AUTOSAR XML (schema 4-0-3)
package /ComponentTypes
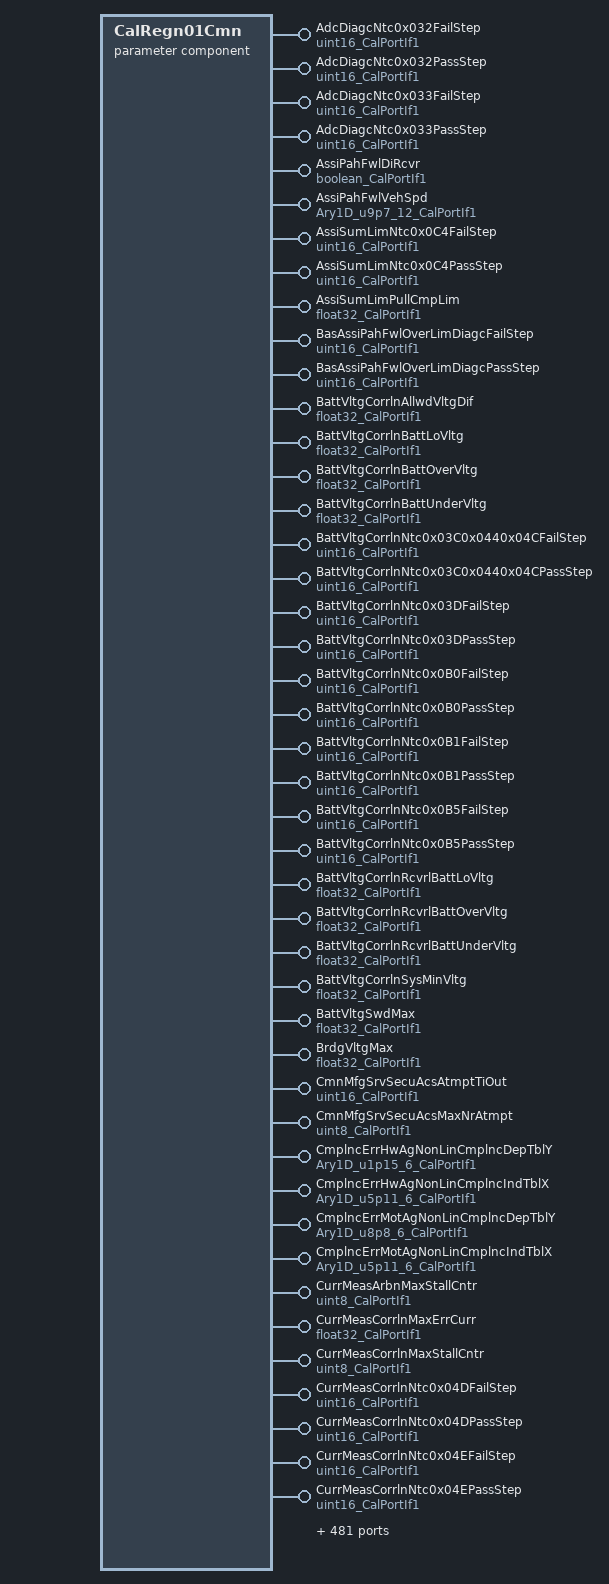
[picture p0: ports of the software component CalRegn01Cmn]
  parameter sw component type CalRegn01Cmn
    525 x provide port:
      AdcDiagcNtc0x032FailStep: parameter-provide-com-spec{init-value=6554, parameter=Val}, provided-interface=uint16_CalPortIf1
      AdcDiagcNtc0x032PassStep: parameter-provide-com-spec{init-value=65, parameter=Val}, provided-interface=uint16_CalPortIf1
      AdcDiagcNtc0x033FailStep: parameter-provide-com-spec{init-value=6554, parameter=Val}, provided-interface=uint16_CalPortIf1
      AdcDiagcNtc0x033PassStep: parameter-provide-com-spec{init-value=65, parameter=Val}, provided-interface=uint16_CalPortIf1
      AssiPahFwlDiRcvr: parameter-provide-com-spec{init-value=0, parameter=Logl}, provided-interface=boolean_CalPortIf1
      AssiPahFwlVehSpd: parameter-provide-com-spec{init-value=[0, 256, 1280, 3200, 6400, 9600, 12800, 19200, 25600, 31872, 32000, 32128], parameter=Ary1D}, provided-interface=Ary1D_u9p7_12_CalPortIf1
      AssiSumLimNtc0x0C4FailStep: parameter-provide-com-spec{init-value=65535, parameter=Val}, provided-interface=uint16_CalPortIf1
      AssiSumLimNtc0x0C4PassStep: parameter-provide-com-spec{init-value=65535, parameter=Val}, provided-interface=uint16_CalPortIf1
      AssiSumLimPullCmpLim: parameter-provide-com-spec{init-value=8.8, parameter=Val}, provided-interface=float32_CalPortIf1
      BasAssiPahFwlOverLimDiagcFailStep: parameter-provide-com-spec{init-value=1311, parameter=Val}, provided-interface=uint16_CalPortIf1
      BasAssiPahFwlOverLimDiagcPassStep: parameter-provide-com-spec{init-value=1311, parameter=Val}, provided-interface=uint16_CalPortIf1
      BattVltgCorrlnAllwdVltgDif: parameter-provide-com-spec{init-value=0.73, parameter=Val}, provided-interface=float32_CalPortIf1
      BattVltgCorrlnBattLoVltg: parameter-provide-com-spec{init-value=10, parameter=Val}, provided-interface=float32_CalPortIf1
      BattVltgCorrlnBattOverVltg: parameter-provide-com-spec{init-value=16, parameter=Val}, provided-interface=float32_CalPortIf1
      BattVltgCorrlnBattUnderVltg: parameter-provide-com-spec{init-value=9, parameter=Val}, provided-interface=float32_CalPortIf1
      BattVltgCorrlnNtc0x03C0x0440x04CFailStep: parameter-provide-com-spec{init-value=410, parameter=Val}, provided-interface=uint16_CalPortIf1
      BattVltgCorrlnNtc0x03C0x0440x04CPassStep: parameter-provide-com-spec{init-value=272, parameter=Val}, provided-interface=uint16_CalPortIf1
      BattVltgCorrlnNtc0x03DFailStep: parameter-provide-com-spec{init-value=410, parameter=Val}, provided-interface=uint16_CalPortIf1
      BattVltgCorrlnNtc0x03DPassStep: parameter-provide-com-spec{init-value=272, parameter=Val}, provided-interface=uint16_CalPortIf1
      BattVltgCorrlnNtc0x0B0FailStep: parameter-provide-com-spec{init-value=327, parameter=Val}, provided-interface=uint16_CalPortIf1
      BattVltgCorrlnNtc0x0B0PassStep: parameter-provide-com-spec{init-value=327, parameter=Val}, provided-interface=uint16_CalPortIf1
      BattVltgCorrlnNtc0x0B1FailStep: parameter-provide-com-spec{init-value=327, parameter=Val}, provided-interface=uint16_CalPortIf1
      BattVltgCorrlnNtc0x0B1PassStep: parameter-provide-com-spec{init-value=327, parameter=Val}, provided-interface=uint16_CalPortIf1
      BattVltgCorrlnNtc0x0B5FailStep: parameter-provide-com-spec{init-value=327, parameter=Val}, provided-interface=uint16_CalPortIf1
      BattVltgCorrlnNtc0x0B5PassStep: parameter-provide-com-spec{init-value=327, parameter=Val}, provided-interface=uint16_CalPortIf1
      BattVltgCorrlnRcvrlBattLoVltg: parameter-provide-com-spec{init-value=10.5, parameter=Val}, provided-interface=float32_CalPortIf1
      BattVltgCorrlnRcvrlBattOverVltg: parameter-provide-com-spec{init-value=15.5, parameter=Val}, provided-interface=float32_CalPortIf1
      BattVltgCorrlnRcvrlBattUnderVltg: parameter-provide-com-spec{init-value=9.5, parameter=Val}, provided-interface=float32_CalPortIf1
      BattVltgCorrlnSysMinVltg: parameter-provide-com-spec{init-value=6, parameter=Val}, provided-interface=float32_CalPortIf1
      BattVltgSwdMax: parameter-provide-com-spec{init-value=16, parameter=Val}, provided-interface=float32_CalPortIf1
      BrdgVltgMax: parameter-provide-com-spec{init-value=26.5, parameter=Val}, provided-interface=float32_CalPortIf1
      CmnMfgSrvSecuAcsAtmptTiOut: parameter-provide-com-spec{init-value=2500, parameter=Val}, provided-interface=uint16_CalPortIf1
      CmnMfgSrvSecuAcsMaxNrAtmpt: parameter-provide-com-spec{init-value=3, parameter=Val}, provided-interface=uint8_CalPortIf1
      CmplncErrHwAgNonLinCmplncDepTblY: parameter-provide-com-spec{init-value=6 x 0, parameter=Ary1D}, provided-interface=Ary1D_u1p15_6_CalPortIf1
      CmplncErrHwAgNonLinCmplncIndTblX: parameter-provide-com-spec{init-value=[0, 1024, 3072, 6144, 10240, 16384], parameter=Ary1D}, provided-interface=Ary1D_u5p11_6_CalPortIf1
      CmplncErrMotAgNonLinCmplncDepTblY: parameter-provide-com-spec{init-value=6 x 0, parameter=Ary1D}, provided-interface=Ary1D_u8p8_6_CalPortIf1
      CmplncErrMotAgNonLinCmplncIndTblX: parameter-provide-com-spec{init-value=[0, 1024, 3072, 6144, 10240, 16384], parameter=Ary1D}, provided-interface=Ary1D_u5p11_6_CalPortIf1
      CurrMeasArbnMaxStallCntr: parameter-provide-com-spec{init-value=20, parameter=Val}, provided-interface=uint8_CalPortIf1
      CurrMeasCorrlnMaxErrCurr: parameter-provide-com-spec{init-value=12, parameter=Val}, provided-interface=float32_CalPortIf1
      CurrMeasCorrlnMaxStallCntr: parameter-provide-com-spec{init-value=200, parameter=Val}, provided-interface=uint8_CalPortIf1
      CurrMeasCorrlnNtc0x04DFailStep: parameter-provide-com-spec{init-value=512, parameter=Val}, provided-interface=uint16_CalPortIf1
      CurrMeasCorrlnNtc0x04DPassStep: parameter-provide-com-spec{init-value=512, parameter=Val}, provided-interface=uint16_CalPortIf1
      CurrMeasCorrlnNtc0x04EFailStep: parameter-provide-com-spec{init-value=512, parameter=Val}, provided-interface=uint16_CalPortIf1
      CurrMeasCorrlnNtc0x04EPassStep: parameter-provide-com-spec{init-value=512, parameter=Val}, provided-interface=uint16_CalPortIf1
      CurrMeasEolFixdPwmPerd: parameter-provide-com-spec{init-value=62500, parameter=Val}, provided-interface=uint32_CalPortIf1
      CurrMeasEolGainMax: parameter-provide-com-spec{init-value=76, parameter=Val}, provided-interface=float32_CalPortIf1
      CurrMeasEolGainMin: parameter-provide-com-spec{init-value=56, parameter=Val}, provided-interface=float32_CalPortIf1
      CurrMeasEolGainNrOfSample: parameter-provide-com-spec{init-value=5, parameter=Val}, provided-interface=uint16_CalPortIf1
      CurrMeasEolGainNumer: parameter-provide-com-spec{init-value=45, parameter=Val}, provided-interface=float32_CalPortIf1
      CurrMeasEolMaxMotVel: parameter-provide-com-spec{init-value=16, parameter=Val}, provided-interface=float32_CalPortIf1
      CurrMeasEolOffsHiBrdgVltgMin: parameter-provide-com-spec{init-value=262500, parameter=Val}, provided-interface=float32_CalPortIf1
      CurrMeasEolOffsHiCmuOffs: parameter-provide-com-spec{init-value=50000, parameter=Val}, provided-interface=uint32_CalPortIf1
      CurrMeasEolOffsLoCmuOffs: parameter-provide-com-spec{init-value=6250, parameter=Val}, provided-interface=uint32_CalPortIf1
      CurrMeasEolOffsMax: parameter-provide-com-spec{init-value=2.8, parameter=Val}, provided-interface=float32_CalPortIf1
      CurrMeasEolOffsMin: parameter-provide-com-spec{init-value=2.3, parameter=Val}, provided-interface=float32_CalPortIf1
      CurrMeasEolOffsNrOfSample: parameter-provide-com-spec{init-value=20, parameter=Val}, provided-interface=uint16_CalPortIf1
      CurrMeasEolTranCntrThd: parameter-provide-com-spec{init-value=5, parameter=Val}, provided-interface=uint8_CalPortIf1
      CurrMeasMinRqrdPhaOnTi: parameter-provide-com-spec{init-value=11000, parameter=Val}, provided-interface=uint32_CalPortIf1
      CurrMeasMotAgCompuDly: parameter-provide-com-spec{init-value=30000, parameter=Val}, provided-interface=uint32_CalPortIf1
      CurrMeasMotCurrAdcVlyWrmIninMax: parameter-provide-com-spec{init-value=3, parameter=Val}, provided-interface=float32_CalPortIf1
      CurrMeasMotCurrAdcVlyWrmIninMin: parameter-provide-com-spec{init-value=2, parameter=Val}, provided-interface=float32_CalPortIf1
      CurrMeasNtc0x05DFailStep: parameter-provide-com-spec{init-value=16384, parameter=Val}, provided-interface=uint16_CalPortIf1
      CurrMeasNtc0x05DPassStep: parameter-provide-com-spec{init-value=16384, parameter=Val}, provided-interface=uint16_CalPortIf1
      CurrMeasNtc0x06DFailStep: parameter-provide-com-spec{init-value=16384, parameter=Val}, provided-interface=uint16_CalPortIf1
      CurrMeasNtc0x06DPassStep: parameter-provide-com-spec{init-value=16384, parameter=Val}, provided-interface=uint16_CalPortIf1
      CurrReasbnDiagcCurrDiagcMotEnvlpTblMax: parameter-provide-com-spec{init-value=4.6, parameter=Val}, provided-interface=float32_CalPortIf1
      CurrReasbnDiagcCurrDiagcPrimErrThd: parameter-provide-com-spec{init-value=20, parameter=Val}, provided-interface=float32_CalPortIf1
      CurrReasbnDiagcCurrDiagcSecdryErrThd: parameter-provide-com-spec{init-value=20, parameter=Val}, provided-interface=float32_CalPortIf1
      CurrReasbnDiagcCurrDiagcSecdryTqLimThd: parameter-provide-com-spec{init-value=0, parameter=Val}, provided-interface=float32_CalPortIf1
      CurrReasbnDiagcDiagFildLim: parameter-provide-com-spec{init-value=10, parameter=Val}, provided-interface=float32_CalPortIf1
      CurrReasbnDiagcDiagVltgLpFilEna: parameter-provide-com-spec{init-value=1, parameter=Logl}, provided-interface=boolean_CalPortIf1
      CurrReasbnDiagcDiagVltgLpFilFrq: parameter-provide-com-spec{init-value=5, parameter=Val}, provided-interface=float32_CalPortIf1
      CurrReasbnDiagcLpFilSca: parameter-provide-com-spec{init-value=0.5, parameter=Val}, provided-interface=float32_CalPortIf1
      CurrReasbnDiagcMotVelHiLim: parameter-provide-com-spec{init-value=1350, parameter=Val}, provided-interface=float32_CalPortIf1
      CurrReasbnDiagcMotVelLoLim: parameter-provide-com-spec{init-value=1, parameter=Val}, provided-interface=float32_CalPortIf1
      CurrReasbnDiagcMotVltgDaxLpFilFrq: parameter-provide-com-spec{init-value=250, parameter=Val}, provided-interface=float32_CalPortIf1
      CurrReasbnDiagcMotVltgQaxDaxFilEna: parameter-provide-com-spec{init-value=1, parameter=Logl}, provided-interface=boolean_CalPortIf1
      CurrReasbnDiagcMotVltgQaxLpFilFrq: parameter-provide-com-spec{init-value=250, parameter=Val}, provided-interface=float32_CalPortIf1
      CurrReasbnDiagcVelLpFilEna: parameter-provide-com-spec{init-value=1, parameter=Logl}, provided-interface=boolean_CalPortIf1
      CurrReasbnDiagcVelLpFilFrq: parameter-provide-com-spec{init-value=125, parameter=Val}, provided-interface=float32_CalPortIf1
      DampgPahFwlAssiAddlDampgX: parameter-provide-com-spec{init-value=[0, 3200, 6400, 9600, 12800, 25600, 32736, 35776], parameter=Ary1D}, provided-interface=Ary1D_u11p5_8_CalPortIf1
      DampgPahFwlAssiAddlDampgY: parameter-provide-com-spec{init-value=[0, 6144, 14336, 14336, 14336, 14336, 14336, 14336], parameter=Ary1D}, provided-interface=Ary1D_u5p11_8_CalPortIf1
      DampgPahFwlDampgCmdAddlDampgX: parameter-provide-com-spec{init-value=[0, 3200, 6400, 9600, 12800, 25600, 32736, 35776], parameter=Ary1D}, provided-interface=Ary1D_u11p5_8_CalPortIf1
      DampgPahFwlDampgCmdAddlDampgY: parameter-provide-com-spec{init-value=[0, 6144, 14336, 14336, 14336, 14336, 14336, 14336], parameter=Ary1D}, provided-interface=Ary1D_u5p11_8_CalPortIf1
      DampgPahFwlDampgCmdFwlOverLimDiagcFailStep: parameter-provide-com-spec{init-value=1311, parameter=Val}, provided-interface=uint16_CalPortIf1
      DampgPahFwlDampgCmdFwlOverLimDiagcPassStep: parameter-provide-com-spec{init-value=1311, parameter=Val}, provided-interface=uint16_CalPortIf1
      DampgPahFwlDftDampgX: parameter-provide-com-spec{init-value=[0, 1184, 2368, 3552, 4736, 5920, 7104, 8288, 9472, 10656, 11840], parameter=Ary1D}, provided-interface=Ary1D_u11p5_11_CalPortIf1
      DampgPahFwlInertiaCmpCmdFwlOverLimDiagcFailStep: parameter-provide-com-spec{init-value=1311, parameter=Val}, provided-interface=uint16_CalPortIf1
      DampgPahFwlInertiaCmpCmdFwlOverLimDiagcPassStep: parameter-provide-com-spec{init-value=1311, parameter=Val}, provided-interface=uint16_CalPortIf1
      DampgPahFwlVehSpd: parameter-provide-com-spec{init-value=[0, 256, 1280, 3200, 6400, 9600, 12800, 19200, 25600, 31872, 32000, 32128], parameter=Ary1D}, provided-interface=Ary1D_u9p7_12_CalPortIf1
      DutyCycThermProtnAbsltCtrlTTblX: parameter-provide-com-spec{init-value=[122, 123, 125, 127], parameter=Ary1D}, provided-interface=Ary1D_s15p0_4_CalPortIf1
      DutyCycThermProtnAbsltCtrlTTqTblY: parameter-provide-com-spec{init-value=[346, 287, 234, 0], parameter=Ary1D}, provided-interface=Ary1D_u9p7_4_CalPortIf1
      DutyCycThermProtnAbsltCuTTblX: parameter-provide-com-spec{init-value=[122, 123, 125, 127], parameter=Ary1D}, provided-interface=Ary1D_s15p0_4_CalPortIf1
      DutyCycThermProtnAbsltCuTTqTblY: parameter-provide-com-spec{init-value=[346, 287, 234, 0], parameter=Ary1D}, provided-interface=Ary1D_u9p7_4_CalPortIf1
      DutyCycThermProtnAbsltMotVelBreakPt: parameter-provide-com-spec{init-value=1.375, parameter=Val}, provided-interface=float32_CalPortIf1
      DutyCycThermProtnAbsltTTqSlewHiLim: parameter-provide-com-spec{init-value=0.3, parameter=Val}, provided-interface=float32_CalPortIf1
      DutyCycThermProtnAbsltTTqSlewLoLim: parameter-provide-com-spec{init-value=0.3, parameter=Val}, provided-interface=float32_CalPortIf1
      DutyCycThermProtnCtrlT: parameter-provide-com-spec{init-value=70, parameter=Val}, provided-interface=float32_CalPortIf1
      DutyCycThermProtnCtrlTSeln: parameter-provide-com-spec{init-value=1, parameter=Logl}, provided-interface=boolean_CalPortIf1
      DutyCycThermProtnDutyCycFildThd: parameter-provide-com-spec{init-value=92, parameter=Val}, provided-interface=u16p0_CalPortIf1
      DutyCycThermProtnIgnOffCtrlEna: parameter-provide-com-spec{init-value=0, parameter=Logl}, provided-interface=boolean_CalPortIf1
      DutyCycThermProtnIgnOffMsgWaitTi: parameter-provide-com-spec{init-value=0.5, parameter=Val}, provided-interface=float32_CalPortIf1
      DutyCycThermProtnLstTblValNonStall: parameter-provide-com-spec{init-value=[128, 128, 128, 44, 44], parameter=Ary1D}, provided-interface=Ary1D_u9p7_5_CalPortIf1
      DutyCycThermProtnLstTblValStall: parameter-provide-com-spec{init-value=[124, 124, 124, 40, 40], parameter=Ary1D}, provided-interface=Ary1D_u9p7_5_CalPortIf1
      DutyCycThermProtnMotPrTSeln: parameter-provide-com-spec{init-value=1, parameter=Logl}, provided-interface=boolean_CalPortIf1
      DutyCycThermProtnMplr1NonStallTblY: parameter-provide-com-spec{init-value=[127, 127, 127, 1630, 1630], parameter=Ary1D}, provided-interface=Ary1D_u3p13_5_CalPortIf1
      DutyCycThermProtnMplr1StallTblY: parameter-provide-com-spec{init-value=[133, 133, 133, 180, 180], parameter=Ary1D}, provided-interface=Ary1D_u3p13_5_CalPortIf1
      DutyCycThermProtnMplr2NonStallTblY: parameter-provide-com-spec{init-value=[159, 159, 159, 281, 281], parameter=Ary1D}, provided-interface=Ary1D_u3p13_5_CalPortIf1
      DutyCycThermProtnMplr2StallTblY: parameter-provide-com-spec{init-value=[167, 167, 167, 310, 310], parameter=Ary1D}, provided-interface=Ary1D_u3p13_5_CalPortIf1
      DutyCycThermProtnMplr3NonStallTblY: parameter-provide-com-spec{init-value=[199, 199, 199, 1282, 1282], parameter=Ary1D}, provided-interface=Ary1D_u3p13_5_CalPortIf1
      DutyCycThermProtnMplr3StallTblY: parameter-provide-com-spec{init-value=[210, 210, 210, 1707, 1707], parameter=Ary1D}, provided-interface=Ary1D_u3p13_5_CalPortIf1
      DutyCycThermProtnMplr4NonStallTblY: parameter-provide-com-spec{init-value=5 x 1, parameter=Ary1D}, provided-interface=Ary1D_u3p13_5_CalPortIf1
      DutyCycThermProtnMplr4StallTblY: parameter-provide-com-spec{init-value=5 x 1, parameter=Ary1D}, provided-interface=Ary1D_u3p13_5_CalPortIf1
      DutyCycThermProtnMplr5NonStallTblY: parameter-provide-com-spec{init-value=[998, 998, 998, 9535, 9535], parameter=Ary1D}, provided-interface=Ary1D_u3p13_5_CalPortIf1
      DutyCycThermProtnMplr5StallTblY: parameter-provide-com-spec{init-value=[998, 998, 998, 9535, 9535], parameter=Ary1D}, provided-interface=Ary1D_u3p13_5_CalPortIf1
      DutyCycThermProtnMplr6NonStallTblY: parameter-provide-com-spec{init-value=5 x 1, parameter=Ary1D}, provided-interface=Ary1D_u3p13_5_CalPortIf1
      DutyCycThermProtnMplr6StallTblY: parameter-provide-com-spec{init-value=5 x 1, parameter=Ary1D}, provided-interface=Ary1D_u3p13_5_CalPortIf1
      DutyCycThermProtnMplrTblX: parameter-provide-com-spec{init-value=[-40, 0, 83, 84, 85], parameter=Ary1D}, provided-interface=Ary1D_s15p0_5_CalPortIf1
      DutyCycThermProtnMplrTSeln: parameter-provide-com-spec{init-value=1, parameter=Logl}, provided-interface=boolean_CalPortIf1
      DutyCycThermProtnSlowFilTSeln: parameter-provide-com-spec{init-value=0, parameter=Logl}, provided-interface=boolean_CalPortIf1
      DutyCycThermProtnThermLimScaFac: parameter-provide-com-spec{init-value=0.5, parameter=Val}, provided-interface=float32_CalPortIf1
      DutyCycThermProtnThermLoadLimTblX: parameter-provide-com-spec{init-value=[0, 76, 80, 84, 88, 92, 96, 100], parameter=Ary1D}, provided-interface=Ary1D_u16p0_8_CalPortIf1
      DutyCycThermProtnThermLoadLimTblY: parameter-provide-com-spec{init-value=[346, 346, 346, 346, 287, 234, 181, 128], parameter=Ary1D}, provided-interface=Ary1D_u9p7_8_CalPortIf1
      DutyCycThermProtnTqCmdSlewDwn: parameter-provide-com-spec{init-value=0.3, parameter=Val}, provided-interface=float32_CalPortIf1
      DutyCycThermProtnTqCmdSlewUp: parameter-provide-com-spec{init-value=0.3, parameter=Val}, provided-interface=float32_CalPortIf1
      EcuTMeasDftT: parameter-provide-com-spec{init-value=60, parameter=Val}, provided-interface=float32_CalPortIf1
      EcuTMeasFilTau: parameter-provide-com-spec{init-value=0.5, parameter=Val}, provided-interface=float32_CalPortIf1
      EcuTMeasNtc0x045FailStep: parameter-provide-com-spec{init-value=3000, parameter=Val}, provided-interface=uint16_CalPortIf1
      EcuTMeasNtc0x045PassStep: parameter-provide-com-spec{init-value=3000, parameter=Val}, provided-interface=uint16_CalPortIf1
      EcuTMeasRngDiagcMax: parameter-provide-com-spec{init-value=145, parameter=Val}, provided-interface=float32_CalPortIf1
      EcuTMeasRngDiagcMin: parameter-provide-com-spec{init-value=-45, parameter=Val}, provided-interface=float32_CalPortIf1
      EcuTMeasScag: parameter-provide-com-spec{init-value=100, parameter=Val}, provided-interface=float32_CalPortIf1
      EcuTMeasScagOffs: parameter-provide-com-spec{init-value=-50, parameter=Val}, provided-interface=float32_CalPortIf1
      ElecPwrCnsCtrlrInpR: parameter-provide-com-spec{init-value=0.0005, parameter=Val}, provided-interface=float32_CalPortIf1
      EotLrngHwAgOverTrvlCnt: parameter-provide-com-spec{init-value=5, parameter=Val}, provided-interface=uint8_CalPortIf1
      EotProtnFwlEotDampgActvBndX: parameter-provide-com-spec{init-value=[-11200, -80, 160, 800, 11200], parameter=Ary1D}, provided-interface=Ary1D_s11p4_5_CalPortIf1
      EotProtnFwlInactvLim: parameter-provide-com-spec{init-value=0.1, parameter=Val}, provided-interface=float32_CalPortIf1
      EotProtnFwlVehSpd: parameter-provide-com-spec{init-value=[0, 2560, 5120, 7680], parameter=Ary1D}, provided-interface=Ary1D_u9p7_4_CalPortIf1
      GateDrv0CtrlNtcNr0x050FailStep: parameter-provide-com-spec{init-value=4096, parameter=Val}, provided-interface=uint16_CalPortIf1
      GateDrv0CtrlNtcNr0x050PassStep: parameter-provide-com-spec{init-value=4096, parameter=Val}, provided-interface=uint16_CalPortIf1
      GateDrv0CtrlNtcNr0x051FailStep: parameter-provide-com-spec{init-value=4096, parameter=Val}, provided-interface=uint16_CalPortIf1
      GateDrv0CtrlNtcNr0x051PassStep: parameter-provide-com-spec{init-value=4096, parameter=Val}, provided-interface=uint16_CalPortIf1
      GateDrv0CtrlNtcNr0x055FailStep: parameter-provide-com-spec{init-value=4096, parameter=Val}, provided-interface=uint16_CalPortIf1
      GateDrv0CtrlNtcNr0x055PassStep: parameter-provide-com-spec{init-value=4096, parameter=Val}, provided-interface=uint16_CalPortIf1
      GateDrv0CtrlUnit0Cfg2WrVal: parameter-provide-com-spec{init-value=2832, parameter=Val}, provided-interface=uint16_CalPortIf1
      GateDrv0CtrlUnit0Cfg3WrVal: parameter-provide-com-spec{init-value=3598, parameter=Val}, provided-interface=uint16_CalPortIf1
      GateDrv0CtrlUnit0Cfg4WrVal: parameter-provide-com-spec{init-value=4622, parameter=Val}, provided-interface=uint16_CalPortIf1
      GateDrv0CtrlUnit0Cfg7WrVal: parameter-provide-com-spec{init-value=7924, parameter=Val}, provided-interface=uint16_CalPortIf1
      GateDrv1CtrlNtcNr0x060FailStep: parameter-provide-com-spec{init-value=4096, parameter=Val}, provided-interface=uint16_CalPortIf1
      GateDrv1CtrlNtcNr0x060PassStep: parameter-provide-com-spec{init-value=4096, parameter=Val}, provided-interface=uint16_CalPortIf1
      GateDrv1CtrlNtcNr0x061FailStep: parameter-provide-com-spec{init-value=4096, parameter=Val}, provided-interface=uint16_CalPortIf1
      GateDrv1CtrlNtcNr0x061PassStep: parameter-provide-com-spec{init-value=4096, parameter=Val}, provided-interface=uint16_CalPortIf1
      GateDrv1CtrlNtcNr0x065FailStep: parameter-provide-com-spec{init-value=4096, parameter=Val}, provided-interface=uint16_CalPortIf1
      GateDrv1CtrlNtcNr0x065PassStep: parameter-provide-com-spec{init-value=4096, parameter=Val}, provided-interface=uint16_CalPortIf1
      GateDrv1CtrlUnit1Cfg2WrVal: parameter-provide-com-spec{init-value=2832, parameter=Val}, provided-interface=uint16_CalPortIf1
      GateDrv1CtrlUnit1Cfg3WrVal: parameter-provide-com-spec{init-value=3598, parameter=Val}, provided-interface=uint16_CalPortIf1
      GateDrv1CtrlUnit1Cfg4WrVal: parameter-provide-com-spec{init-value=4622, parameter=Val}, provided-interface=uint16_CalPortIf1
      GateDrv1CtrlUnit1Cfg7WrVal: parameter-provide-com-spec{init-value=7924, parameter=Val}, provided-interface=uint16_CalPortIf1
      GmFctDiArbnEotHwAgThd: parameter-provide-com-spec{init-value=20, parameter=Val}, provided-interface=float32_CalPortIf1
      GmFctDiArbnEotTi: parameter-provide-com-spec{init-value=1, parameter=Val}, provided-interface=float32_CalPortIf1
      GmFctDiArbnOnCentrHwAgThd: parameter-provide-com-spec{init-value=5, parameter=Val}, provided-interface=float32_CalPortIf1
      GmFctDiArbnOnCentrHwTqThd: parameter-provide-com-spec{init-value=0, parameter=Val}, provided-interface=float32_CalPortIf1
      GmFctDiArbnOnCentrTi: parameter-provide-com-spec{init-value=1, parameter=Val}, provided-interface=float32_CalPortIf1
      GmFctDiArbnSrvTi: parameter-provide-com-spec{init-value=15, parameter=Val}, provided-interface=float32_CalPortIf1
      GmMsg0C5BusHiSpdInvldTiOut: parameter-provide-com-spec{init-value=1000, parameter=Val}, provided-interface=uint16_CalPortIf1
      GmMsg0C5BusHiSpdMissTiOut: parameter-provide-com-spec{init-value=500, parameter=Val}, provided-interface=uint16_CalPortIf1
      GmMsg0C5BusHiSpdRstTiOut: parameter-provide-com-spec{init-value=5, parameter=Val}, provided-interface=uint16_CalPortIf1
      GmMsg0C5BusHiSpdSeqNrTiOut: parameter-provide-com-spec{init-value=5, parameter=Val}, provided-interface=uint16_CalPortIf1
      GmMsg0C9BusHiSpdInvldTiOut: parameter-provide-com-spec{init-value=1000, parameter=Val}, provided-interface=uint16_CalPortIf1
      GmMsg0C9BusHiSpdMissTiOut: parameter-provide-com-spec{init-value=500, parameter=Val}, provided-interface=uint16_CalPortIf1
      GmMsg0C9BusHiSpdVehSpdThd: parameter-provide-com-spec{init-value=10, parameter=Val}, provided-interface=float32_CalPortIf1
      GmMsg17DBusHiSpdInvldTiOut: parameter-provide-com-spec{init-value=1000, parameter=Val}, provided-interface=uint16_CalPortIf1
      GmMsg17DBusHiSpdMissTiOut: parameter-provide-com-spec{init-value=500, parameter=Val}, provided-interface=uint16_CalPortIf1
      GmMsg180BusChassisExpInvldProtnValTiOut: parameter-provide-com-spec{init-value=500, parameter=Val}, provided-interface=uint16_CalPortIf1
      GmMsg180BusChassisExpMissTiOut: parameter-provide-com-spec{init-value=1000, parameter=Val}, provided-interface=uint16_CalPortIf1
      GmMsg180BusChassisExpRollgCntrInvldTiOut: parameter-provide-com-spec{init-value=500, parameter=Val}, provided-interface=uint16_CalPortIf1
      GmMsg180BusChassisExpTqPolarity: parameter-provide-com-spec{init-value=1, parameter=Val}, provided-interface=sint8_CalPortIf1
      GmMsg180BusHiSpdCrcInvldTiOut: parameter-provide-com-spec{init-value=500, parameter=Val}, provided-interface=uint16_CalPortIf1
      GmMsg180BusHiSpdMissTiOut: parameter-provide-com-spec{init-value=500, parameter=Val}, provided-interface=uint16_CalPortIf1
      GmMsg180BusHiSpdRollgCntrInvldTiOut: parameter-provide-com-spec{init-value=500, parameter=Val}, provided-interface=uint16_CalPortIf1
      GmMsg180BusHiSpdTqPolarity: parameter-provide-com-spec{init-value=1, parameter=Val}, provided-interface=sint8_CalPortIf1
      GmMsg182BusChassisExpInvldTiOut: parameter-provide-com-spec{init-value=500, parameter=Val}, provided-interface=uint16_CalPortIf1
      GmMsg182BusChassisExpMissTiOut: parameter-provide-com-spec{init-value=1000, parameter=Val}, provided-interface=uint16_CalPortIf1
      GmMsg184BusHiSpdHandsOnThd: parameter-provide-com-spec{init-value=0.5, parameter=Val}, provided-interface=float32_CalPortIf1
      GmMsg184BusHiSpdTqPolarity: parameter-provide-com-spec{init-value=1, parameter=Val}, provided-interface=sint8_CalPortIf1
      GmMsg1CaBusChassisExpTqPolarity: parameter-provide-com-spec{init-value=1, parameter=Val}, provided-interface=sint8_CalPortIf1
      GmMsg1E9BusHiSpdAbsFaildTiOut: parameter-provide-com-spec{init-value=1000, parameter=Val}, provided-interface=uint16_CalPortIf1
      GmMsg1E9BusHiSpdLatADft: parameter-provide-com-spec{init-value=0.101937, parameter=Val}, provided-interface=float32_CalPortIf1
      GmMsg1E9BusHiSpdLatAInvldTiOut: parameter-provide-com-spec{init-value=5000, parameter=Val}, provided-interface=uint16_CalPortIf1
      GmMsg1E9BusHiSpdMissTiOut: parameter-provide-com-spec{init-value=500, parameter=Val}, provided-interface=uint16_CalPortIf1
      GmMsg1E9BusHiSpdTcsDisadTiOut: parameter-provide-com-spec{init-value=1000, parameter=Val}, provided-interface=uint16_CalPortIf1
      GmMsg1E9BusHiSpdVehDynCtrlStTiOut: parameter-provide-com-spec{init-value=1000, parameter=Val}, provided-interface=uint16_CalPortIf1
      GmMsg1E9BusHiSpdVehStabyEnhmtActvVldTiOut: parameter-provide-com-spec{init-value=1000, parameter=Val}, provided-interface=uint16_CalPortIf1
      GmMsg1E9BusHiSpdYawRateDft: parameter-provide-com-spec{init-value=50, parameter=Val}, provided-interface=float32_CalPortIf1
      GmMsg1E9BusHiSpdYawRateInvldTiOut: parameter-provide-com-spec{init-value=5000, parameter=Val}, provided-interface=uint16_CalPortIf1
      GmMsg1F1BusHiSpdMissTiOut: parameter-provide-com-spec{init-value=500, parameter=Val}, provided-interface=uint16_CalPortIf1
      GmMsg1F5BusHiSpdInvldTiOut: parameter-provide-com-spec{init-value=500, parameter=Val}, provided-interface=uint16_CalPortIf1
      GmMsg1F5BusHiSpdMissTiOut: parameter-provide-com-spec{init-value=500, parameter=Val}, provided-interface=uint16_CalPortIf1
      GmMsg214BusHiSpdAbsActvProtdInvldTiOut: parameter-provide-com-spec{init-value=500, parameter=Val}, provided-interface=uint16_CalPortIf1
      GmMsg214BusHiSpdAbsActvProtdProtnValInvldTiOut: parameter-provide-com-spec{init-value=500, parameter=Val}, provided-interface=uint16_CalPortIf1
      GmMsg214BusHiSpdAbsActvProtdRollgCntrInvldTiOut: parameter-provide-com-spec{init-value=500, parameter=Val}, provided-interface=uint16_CalPortIf1
      GmMsg214BusHiSpdMissTiOut: parameter-provide-com-spec{init-value=500, parameter=Val}, provided-interface=uint16_CalPortIf1
      GmMsg214BusHiSpdRdntVehStabyEnhmtActvInvldTiOut: parameter-provide-com-spec{init-value=500, parameter=Val}, provided-interface=uint16_CalPortIf1
      GmMsg214BusHiSpdRdntVehStabyEnhmtActvRollgCntrInvldTiOut: parameter-provide-com-spec{init-value=500, parameter=Val}, provided-interface=uint16_CalPortIf1
      GmMsg232BusHiSpdMissTiOut: parameter-provide-com-spec{init-value=500, parameter=Val}, provided-interface=uint16_CalPortIf1
      GmMsg337BusChassisExpInvldDiagcTiOut: parameter-provide-com-spec{init-value=500, parameter=Val}, provided-interface=uint16_CalPortIf1
      GmMsg337BusChassisExpInvldProtnValTiOut: parameter-provide-com-spec{init-value=5, parameter=Val}, provided-interface=uint16_CalPortIf1
      GmMsg337BusChassisExpInvldRollgCntrTiOut: parameter-provide-com-spec{init-value=5, parameter=Val}, provided-interface=uint16_CalPortIf1
      GmMsg337BusChassisExpMissTiOut: parameter-provide-com-spec{init-value=1000, parameter=Val}, provided-interface=uint16_CalPortIf1
      GmMsg337BusChassisExpTarAgPolarity: parameter-provide-com-spec{init-value=1, parameter=Val}, provided-interface=sint8_CalPortIf1
      GmMsg348BusChassisExpInvldTiOut: parameter-provide-com-spec{init-value=1000, parameter=Val}, provided-interface=uint16_CalPortIf1
      GmMsg348BusChassisExpMissTiOut: parameter-provide-com-spec{init-value=500, parameter=Val}, provided-interface=uint16_CalPortIf1
      GmMsg348BusChassisExpStuckTiOut: parameter-provide-com-spec{init-value=500, parameter=Val}, provided-interface=uint16_CalPortIf1
      GmMsg348BusHiSpdInvldTiOut: parameter-provide-com-spec{init-value=1000, parameter=Val}, provided-interface=uint16_CalPortIf1
      GmMsg348BusHiSpdMissTiOut: parameter-provide-com-spec{init-value=500, parameter=Val}, provided-interface=uint16_CalPortIf1
      GmMsg348BusHiSpdStuckTiOut: parameter-provide-com-spec{init-value=500, parameter=Val}, provided-interface=uint16_CalPortIf1
      GmMsg34ABusChassisExpInvldTiOut: parameter-provide-com-spec{init-value=1000, parameter=Val}, provided-interface=uint16_CalPortIf1
      GmMsg34ABusChassisExpMissTiOut: parameter-provide-com-spec{init-value=500, parameter=Val}, provided-interface=uint16_CalPortIf1
      GmMsg34ABusChassisExpStuckTiOut: parameter-provide-com-spec{init-value=500, parameter=Val}, provided-interface=uint16_CalPortIf1
      GmMsg34ABusHiSpdInvldTiOut: parameter-provide-com-spec{init-value=1000, parameter=Val}, provided-interface=uint16_CalPortIf1
      GmMsg34ABusHiSpdMissTiOut: parameter-provide-com-spec{init-value=500, parameter=Val}, provided-interface=uint16_CalPortIf1
      GmMsg34ABusHiSpdStuckTiOut: parameter-provide-com-spec{init-value=500, parameter=Val}, provided-interface=uint16_CalPortIf1
      GmMsg3F1BusHiSpdAmbTDft: parameter-provide-com-spec{init-value=25, parameter=Val}, provided-interface=float32_CalPortIf1
      GmMsg3F1BusHiSpdInvldTiOut: parameter-provide-com-spec{init-value=5000, parameter=Val}, provided-interface=uint16_CalPortIf1
      GmMsg3F1BusHiSpdMissTiOut: parameter-provide-com-spec{init-value=500, parameter=Val}, provided-interface=uint16_CalPortIf1
      GmMsg4D1BusHiSpdEngOilTDft: parameter-provide-com-spec{init-value=60, parameter=Val}, provided-interface=float32_CalPortIf1
      GmMsg4D1BusHiSpdInvldTiOut: parameter-provide-com-spec{init-value=5000, parameter=Val}, provided-interface=uint16_CalPortIf1
      GmMsg4D1BusHiSpdMissTiOut: parameter-provide-com-spec{init-value=500, parameter=Val}, provided-interface=uint16_CalPortIf1
      GmMsg500BusHiSpdMissTiOut: parameter-provide-com-spec{init-value=500, parameter=Val}, provided-interface=uint16_CalPortIf1
      GmMsg500BusHiSpdWhlPlsPerRevDft: parameter-provide-com-spec{init-value=48, parameter=Val}, provided-interface=uint8_CalPortIf1
      GmMsg500BusHiSpdWhlRotlStsTiStampReslDft: parameter-provide-com-spec{init-value=0.000004094, parameter=Val}, provided-interface=float32_CalPortIf1
      HiFrqAssiPahFwlOverLimDiagcFailStep: parameter-provide-com-spec{init-value=1311, parameter=Val}, provided-interface=uint16_CalPortIf1
      HiFrqAssiPahFwlOverLimDiagcPassStep: parameter-provide-com-spec{init-value=1311, parameter=Val}, provided-interface=uint16_CalPortIf1
      HwAgSnsrlsCorrdPinionAgHwConf: parameter-provide-com-spec{init-value=1, parameter=Val}, provided-interface=float32_CalPortIf1
      HwAgSnsrlsFCentrHwConf: parameter-provide-com-spec{init-value=1, parameter=Val}, provided-interface=float32_CalPortIf1
      HwAgSnsrlsPinionTqFilFrq: parameter-provide-com-spec{init-value=0.035, parameter=Val}, provided-interface=float32_CalPortIf1
      HwAgSnsrlsRelHwAgFil1Frq: parameter-provide-com-spec{init-value=0.025, parameter=Val}, provided-interface=float32_CalPortIf1
      HwAgSnsrlsRelHwAgFil2Frq: parameter-provide-com-spec{init-value=0.025, parameter=Val}, provided-interface=float32_CalPortIf1
      HwAgSnsrlsSmotngCoeff: parameter-provide-com-spec{init-value=0.2, parameter=Val}, provided-interface=float32_CalPortIf1
      HwAgSnsrlsSmotngStepThd: parameter-provide-com-spec{init-value=5, parameter=Val}, provided-interface=float32_CalPortIf1
      HwAgSnsrlsStordPinionConf: parameter-provide-com-spec{init-value=0.1, parameter=Val}, provided-interface=float32_CalPortIf1
      HwAgSnsrlsStordPinionConfThd: parameter-provide-com-spec{init-value=0.1, parameter=Val}, provided-interface=float32_CalPortIf1
      HwAgSnsrlsVehDynDifThd: parameter-provide-com-spec{init-value=5, parameter=Val}, provided-interface=float32_CalPortIf1
      HwAgSnsrlsVehDynHwConf: parameter-provide-com-spec{init-value=0, parameter=Val}, provided-interface=float32_CalPortIf1
      HwAgSnsrlsVehDynMotVelThd: parameter-provide-com-spec{init-value=20, parameter=Val}, provided-interface=float32_CalPortIf1
      HwAgSnsrlsVehDynPinionTqThd: parameter-provide-com-spec{init-value=3, parameter=Val}, provided-interface=float32_CalPortIf1
      HwAgSnsrlsVehDynTmr1Thd: parameter-provide-com-spec{init-value=1500, parameter=Val}, provided-interface=uint32_CalPortIf1
      HwAgSnsrlsVehDynTmr2Thd: parameter-provide-com-spec{init-value=2000, parameter=Val}, provided-interface=uint32_CalPortIf1
      HwAgSnsrlsWhlFrqThd: parameter-provide-com-spec{init-value=0.2, parameter=Val}, provided-interface=float32_CalPortIf1
      HwAgSnsrlsWhlSpdHwAgCoeff1: parameter-provide-com-spec{init-value=4000, parameter=Val}, provided-interface=float32_CalPortIf1
      HwAgSnsrlsWhlSpdHwAgCoeff2: parameter-provide-com-spec{init-value=0, parameter=Val}, provided-interface=float32_CalPortIf1
      HwAgSnsrlsWhlSpdHwAgThd: parameter-provide-com-spec{init-value=600, parameter=Val}, provided-interface=float32_CalPortIf1
      HwAgSnsrlsWhlSpdHwConf: parameter-provide-com-spec{init-value=0.2, parameter=Val}, provided-interface=float32_CalPortIf1
      HwAgSnsrlsWhlSpdRatThd: parameter-provide-com-spec{init-value=1e-05, parameter=Val}, provided-interface=float32_CalPortIf1
      HwAgSnsrlsWhlSpdTmrThd: parameter-provide-com-spec{init-value=500, parameter=Val}, provided-interface=uint32_CalPortIf1
      HwAgSnsrlsWhlSpdVehSpdThd: parameter-provide-com-spec{init-value=0.1, parameter=Val}, provided-interface=float32_CalPortIf1
      HwAgSysArbnHwAgConf1Snsr: parameter-provide-com-spec{init-value=1, parameter=Val}, provided-interface=float32_CalPortIf1
      HwAgSysArbnHwAgConf2Snsr: parameter-provide-com-spec{init-value=1, parameter=Val}, provided-interface=float32_CalPortIf1
      HwAgSysArbnHwAgConfNoSnsr: parameter-provide-com-spec{init-value=0, parameter=Val}, provided-interface=float32_CalPortIf1
      HwAgSysArbnHwAgCorrdCorrlnThd: parameter-provide-com-spec{init-value=1, parameter=Val}, provided-interface=float32_CalPortIf1
      HwAgSysArbnHwAgCorrlnFailDebStep: parameter-provide-com-spec{init-value=132, parameter=Val}, provided-interface=uint16_CalPortIf1
      HwAgSysArbnHwAgCorrlnPassDebStep: parameter-provide-com-spec{init-value=132, parameter=Val}, provided-interface=uint16_CalPortIf1
      HwAgSysArbnHwAgCorrlnRng: parameter-provide-com-spec{init-value=5, parameter=Val}, provided-interface=float32_CalPortIf1
      HwAgSysArbnHwAgSlewRate: parameter-provide-com-spec{init-value=100, parameter=Val}, provided-interface=float32_CalPortIf1
      HwAgSysArbnHwAgSnsrlsCorrlnThd: parameter-provide-com-spec{init-value=1, parameter=Val}, provided-interface=float32_CalPortIf1
      HwAgSysArbnHwAgSnsrlsKineThd: parameter-provide-com-spec{init-value=1500, parameter=Val}, provided-interface=float32_CalPortIf1
      HwAgSysArbnHwAgToMotAgCorrlnElpdTiLim: parameter-provide-com-spec{init-value=86400, parameter=Val}, provided-interface=uint32_CalPortIf1
      HwAgSysArbnSerlComHwAgCorrdConf: parameter-provide-com-spec{init-value=1, parameter=Val}, provided-interface=float32_CalPortIf1
      HwAgSysArbnSerlComHwAgSnsrlsConf: parameter-provide-com-spec{init-value=1, parameter=Val}, provided-interface=float32_CalPortIf1
      HwAgSysArbnSlewRateTmr: parameter-provide-com-spec{init-value=10000, parameter=Val}, provided-interface=float32_CalPortIf1
      HwAgTrajGennAgMax: parameter-provide-com-spec{init-value=100, parameter=Val}, provided-interface=float32_CalPortIf1
      HwAgTrajGennAMax: parameter-provide-com-spec{init-value=500, parameter=Val}, provided-interface=float32_CalPortIf1
      HwAgTrajGennVelMax: parameter-provide-com-spec{init-value=50, parameter=Val}, provided-interface=float32_CalPortIf1
      HwTq2MeasHwTq2PrtclFltFailStep: parameter-provide-com-spec{init-value=2521, parameter=Val}, provided-interface=uint16_CalPortIf1
      HwTq2MeasHwTq2PrtclFltPassStep: parameter-provide-com-spec{init-value=1000, parameter=Val}, provided-interface=uint16_CalPortIf1
      HwTq3MeasHwTq3PrtclFltFailStep: parameter-provide-com-spec{init-value=2521, parameter=Val}, provided-interface=uint16_CalPortIf1
      HwTq3MeasHwTq3PrtclFltPassStep: parameter-provide-com-spec{init-value=1000, parameter=Val}, provided-interface=uint16_CalPortIf1
      HwTqArbnMaxStallTqA: parameter-provide-com-spec{init-value=10, parameter=Val}, provided-interface=uint8_CalPortIf1
      HwTqArbnMaxStallTqB: parameter-provide-com-spec{init-value=10, parameter=Val}, provided-interface=uint8_CalPortIf1
      HwTqArbnMaxStallTqC: parameter-provide-com-spec{init-value=10, parameter=Val}, provided-interface=uint8_CalPortIf1
      HwTqArbnMaxStallTqD: parameter-provide-com-spec{init-value=10, parameter=Val}, provided-interface=uint8_CalPortIf1
      HwTqCorrlnChACmnModCmpLpFilActvnThd: parameter-provide-com-spec{init-value=0.2857143, parameter=Val}, provided-interface=float32_CalPortIf1
      HwTqCorrlnChACmnModCmpLpFilFrq: parameter-provide-com-spec{init-value=0.01989437, parameter=Val}, provided-interface=float32_CalPortIf1
      HwTqCorrlnChACmnModCmpLpFilOutpLim: parameter-provide-com-spec{init-value=0.5714, parameter=Val}, provided-interface=float32_CalPortIf1
      HwTqCorrlnChAImdtCorrlnChkFailThd: parameter-provide-com-spec{init-value=2.85, parameter=Val}, provided-interface=float32_CalPortIf1
      HwTqCorrlnChAImdtCorrlnChkPassThd: parameter-provide-com-spec{init-value=2, parameter=Val}, provided-interface=float32_CalPortIf1
      HwTqCorrlnChAStabStClrFltThd: parameter-provide-com-spec{init-value=2.515, parameter=Val}, provided-interface=float32_CalPortIf1
      HwTqCorrlnChAStabStLpFilFrq: parameter-provide-com-spec{init-value=0.01989437, parameter=Val}, provided-interface=float32_CalPortIf1
      HwTqCorrlnChAStabStSetFltThd: parameter-provide-com-spec{init-value=2.85, parameter=Val}, provided-interface=float32_CalPortIf1
      HwTqCorrlnChATqSumMaxLim: parameter-provide-com-spec{init-value=20, parameter=Val}, provided-interface=float32_CalPortIf1
      HwTqCorrlnChATraLpFilX: parameter-provide-com-spec{init-value=[0, 1783, 3560, 5342, 7125, 8902, 10685, 12467, 14245, 16027, 17810, 19587, 21370, 23152, 24935, 26712, 28495], parameter=Ary1D}, provided-interface=Ary1D_u5p11_17_CalPortIf1
      HwTqCorrlnChATraLpFilY: parameter-provide-com-spec{init-value=[34873, 34873, 34873, 34873, 19910, 12411, 9199, 7350, 6137, 5272, 4623, 4119, 3714, 3382, 3104, 2870, 2668], parameter=Ary1D}, provided-interface=Ary1D_u6p10_17_CalPortIf1
      HwTqCorrlnChATraSumClrFltThd: parameter-provide-com-spec{init-value=1.425, parameter=Val}, provided-interface=float32_CalPortIf1
      HwTqCorrlnChATraSumSetFltThd: parameter-provide-com-spec{init-value=2.85, parameter=Val}, provided-interface=float32_CalPortIf1
      HwTqCorrlnChBCmnModCmpLpFilActvnThd: parameter-provide-com-spec{init-value=0.2857143, parameter=Val}, provided-interface=float32_CalPortIf1
      HwTqCorrlnChBCmnModCmpLpFilFrq: parameter-provide-com-spec{init-value=0.01989437, parameter=Val}, provided-interface=float32_CalPortIf1
      HwTqCorrlnChBCmnModCmpLpFilOutpLim: parameter-provide-com-spec{init-value=0.5714, parameter=Val}, provided-interface=float32_CalPortIf1
      HwTqCorrlnChBImdtCorrlnChkFailThd: parameter-provide-com-spec{init-value=2.85, parameter=Val}, provided-interface=float32_CalPortIf1
      HwTqCorrlnChBImdtCorrlnChkPassThd: parameter-provide-com-spec{init-value=2, parameter=Val}, provided-interface=float32_CalPortIf1
      HwTqCorrlnChBStabStClrFltThd: parameter-provide-com-spec{init-value=2.515, parameter=Val}, provided-interface=float32_CalPortIf1
      HwTqCorrlnChBStabStLpFilFrq: parameter-provide-com-spec{init-value=0.01989437, parameter=Val}, provided-interface=float32_CalPortIf1
      HwTqCorrlnChBStabStSetFltThd: parameter-provide-com-spec{init-value=2.85, parameter=Val}, provided-interface=float32_CalPortIf1
      HwTqCorrlnChBTqSumMaxLim: parameter-provide-com-spec{init-value=20, parameter=Val}, provided-interface=float32_CalPortIf1
      HwTqCorrlnChBTraLpFilX: parameter-provide-com-spec{init-value=[0, 1783, 3560, 5342, 7125, 8902, 10685, 12467, 14245, 16027, 17810, 19587, 21370, 23152, 24935, 26712, 28495], parameter=Ary1D}, provided-interface=Ary1D_u5p11_17_CalPortIf1
      HwTqCorrlnChBTraLpFilY: parameter-provide-com-spec{init-value=[34873, 34873, 34873, 34873, 19910, 12411, 9199, 7350, 6137, 5272, 4623, 4119, 3714, 3382, 3104, 2870, 2668], parameter=Ary1D}, provided-interface=Ary1D_u6p10_17_CalPortIf1
      HwTqCorrlnChBTraSumClrFltThd: parameter-provide-com-spec{init-value=1.425, parameter=Val}, provided-interface=float32_CalPortIf1
      HwTqCorrlnChBTraSumSetFltThd: parameter-provide-com-spec{init-value=2.85, parameter=Val}, provided-interface=float32_CalPortIf1
      HwTqCorrlnMaxStallTqA: parameter-provide-com-spec{init-value=10, parameter=Val}, provided-interface=uint8_CalPortIf1
      HwTqCorrlnMaxStallTqB: parameter-provide-com-spec{init-value=10, parameter=Val}, provided-interface=uint8_CalPortIf1
      HwTqCorrlnMaxStallTqC: parameter-provide-com-spec{init-value=10, parameter=Val}, provided-interface=uint8_CalPortIf1
      HwTqCorrlnMaxStallTqD: parameter-provide-com-spec{init-value=10, parameter=Val}, provided-interface=uint8_CalPortIf1
      ImcArbnEcuIninTiOutThd: parameter-provide-com-spec{init-value=500, parameter=Val}, provided-interface=uint32_CalPortIf1
      ImcArbnFrmFltThd: parameter-provide-com-spec{init-value=10, parameter=Val}, provided-interface=uint8_CalPortIf1
      LoaMgrCurrIvtrMtgtnRate: parameter-provide-com-spec{init-value=1, parameter=Val}, provided-interface=float32_CalPortIf1
      LoaMgrCurrIvtrMtgtnSca: parameter-provide-com-spec{init-value=1, parameter=Val}, provided-interface=float32_CalPortIf1
      LoaMgrCurrIvtrMtgtnScaZeroEna: parameter-provide-com-spec{init-value=0, parameter=Logl}, provided-interface=boolean_CalPortIf1
      LoaMgrCurrMeasIdptSig0Resp: parameter-provide-com-spec{init-value=2, parameter=Val}, provided-interface=uint8_CalPortIf1
      LoaMgrCurrMeasIdptSig1Resp: parameter-provide-com-spec{init-value=0, parameter=Val}, provided-interface=uint8_CalPortIf1
      LoaMgrCurrMeasIdptSig2Resp: parameter-provide-com-spec{init-value=0, parameter=Val}, provided-interface=uint8_CalPortIf1
      LoaMgrCurrMeasIdptSigFltThd: parameter-provide-com-spec{init-value=0, parameter=Val}, provided-interface=uint8_CalPortIf1
      LoaMgrCurrMeasMtgtnRate: parameter-provide-com-spec{init-value=1, parameter=Val}, provided-interface=float32_CalPortIf1
      LoaMgrCurrMeasMtgtnSca: parameter-provide-com-spec{init-value=1, parameter=Val}, provided-interface=float32_CalPortIf1
      LoaMgrCurrMeasMtgtnScaZeroEna: parameter-provide-com-spec{init-value=1, parameter=Logl}, provided-interface=boolean_CalPortIf1
      LoaMgrFadeOutStRate: parameter-provide-com-spec{init-value=1, parameter=Val}, provided-interface=float32_CalPortIf1
      LoaMgrHwTqIdptSig0NoTqLoaResp: parameter-provide-com-spec{init-value=4, parameter=Val}, provided-interface=uint8_CalPortIf1
      LoaMgrHwTqIdptSig1NoTqLoaResp: parameter-provide-com-spec{init-value=4, parameter=Val}, provided-interface=uint8_CalPortIf1
      LoaMgrHwTqIdptSig2Resp: parameter-provide-com-spec{init-value=0, parameter=Val}, provided-interface=uint8_CalPortIf1
      LoaMgrHwTqIdptSig4Resp: parameter-provide-com-spec{init-value=0, parameter=Val}, provided-interface=uint8_CalPortIf1
      LoaMgrHwTqIdptSigFltThd: parameter-provide-com-spec{init-value=1, parameter=Val}, provided-interface=uint8_CalPortIf1
      LoaMgrHwTqLoaAvlResp: parameter-provide-com-spec{init-value=2, parameter=Val}, provided-interface=uint8_CalPortIf1
      LoaMgrIvtrIdptSig0Resp: parameter-provide-com-spec{init-value=5, parameter=Val}, provided-interface=uint8_CalPortIf1
      LoaMgrIvtrIdptSig1Resp: parameter-provide-com-spec{init-value=2, parameter=Val}, provided-interface=uint8_CalPortIf1
      LoaMgrIvtrIdptSig2Resp: parameter-provide-com-spec{init-value=0, parameter=Val}, provided-interface=uint8_CalPortIf1
      LoaMgrIvtrIdptSigFltThd: parameter-provide-com-spec{init-value=0, parameter=Val}, provided-interface=uint8_CalPortIf1
      LoaMgrIvtrMtgtnRate: parameter-provide-com-spec{init-value=1, parameter=Val}, provided-interface=float32_CalPortIf1
      LoaMgrIvtrMtgtnSca: parameter-provide-com-spec{init-value=1, parameter=Val}, provided-interface=float32_CalPortIf1
      LoaMgrIvtrMtgtnScaZeroEna: parameter-provide-com-spec{init-value=0, parameter=Logl}, provided-interface=boolean_CalPortIf1
      LoaMgrLimdStRate: parameter-provide-com-spec{init-value=1, parameter=Val}, provided-interface=float32_CalPortIf1
      LoaMgrLimdStSca: parameter-provide-com-spec{init-value=1, parameter=Val}, provided-interface=float32_CalPortIf1
      LoaMgrMotAgAvlSnsrlsResp: parameter-provide-com-spec{init-value=2, parameter=Val}, provided-interface=uint8_CalPortIf1
      LoaMgrMotAgIdptSig0NoSnsrlsResp: parameter-provide-com-spec{init-value=5, parameter=Val}, provided-interface=uint8_CalPortIf1
      LoaMgrMotAgIdptSig1NoSnsrlsResp: parameter-provide-com-spec{init-value=5, parameter=Val}, provided-interface=uint8_CalPortIf1
      LoaMgrMotAgIdptSig2Resp: parameter-provide-com-spec{init-value=1, parameter=Val}, provided-interface=uint8_CalPortIf1
      LoaMgrMotAgIdptSig3Resp: parameter-provide-com-spec{init-value=0, parameter=Val}, provided-interface=uint8_CalPortIf1
      LoaMgrMotAgIdptSigFltThd: parameter-provide-com-spec{init-value=2, parameter=Val}, provided-interface=uint8_CalPortIf1
      LoaMgrMotAgMtgtnRate: parameter-provide-com-spec{init-value=1, parameter=Val}, provided-interface=float32_CalPortIf1
      LoaMgrMotAgMtgtnSca: parameter-provide-com-spec{init-value=1, parameter=Val}, provided-interface=float32_CalPortIf1
      LoaMgrMotAgMtgtnScaZeroEna: parameter-provide-com-spec{init-value=0, parameter=Logl}, provided-interface=boolean_CalPortIf1
      MotCtrlPrmEstimnFetRNom: parameter-provide-com-spec{init-value=0.0052, parameter=Val}, provided-interface=float32_CalPortIf1
      MotCtrlPrmEstimnFetThermCoeff: parameter-provide-com-spec{init-value=0.005, parameter=Val}, provided-interface=float32_CalPortIf1
      MotCtrlPrmEstimnMagThermCoeff: parameter-provide-com-spec{init-value=-0.001, parameter=Val}, provided-interface=float32_CalPortIf1
      MotCtrlPrmEstimnMotBackEmfConHiLim: parameter-provide-com-spec{init-value=0.045, parameter=Val}, provided-interface=float32_CalPortIf1
      MotCtrlPrmEstimnMotBackEmfConLoLim: parameter-provide-com-spec{init-value=0.031, parameter=Val}, provided-interface=float32_CalPortIf1
      MotCtrlPrmEstimnMotBackEmfConNom: parameter-provide-com-spec{init-value=0.04, parameter=Val}, provided-interface=float32_CalPortIf1
      MotCtrlPrmEstimnMotBackEmfConSatnScaIvtrLoaMtgtn: parameter-provide-com-spec{init-value=1, parameter=Val}, provided-interface=float32_CalPortIf1
      MotCtrlPrmEstimnMotBackEmfConSatnX: parameter-provide-com-spec{init-value=[0, 1280, 2560, 3840, 5120, 6400, 7680, 8960, 10240, 11520, 12800, 14080, 15360, 16640, 19200, 21760], parameter=Ary1D}, provided-interface=Ary1D_u9p7_16_CalPortIf1
      MotCtrlPrmEstimnMotBackEmfConSatnY: parameter-provide-com-spec{init-value=[16384, 16384, 16384, 16384, 16384, 16384, 16384, 16384, 16384, 16384, 16384, 16370, 16336, 16276, 16095, 15869], parameter=Ary1D}, provided-interface=Ary1D_u2p14_16_CalPortIf1
      MotCtrlPrmEstimnMotCurrDaxInduSatnBilnrSeln: parameter-provide-com-spec{init-value=[0, 3200, 6400, 9600, 12800, 16000], parameter=Ary1D}, provided-interface=Ary1D_u9p7_6_CalPortIf1
      MotCtrlPrmEstimnMotCurrQaxInduSatnX: parameter-provide-com-spec{init-value=[0, 3200, 6400, 9600, 12800, 16000, 19200], parameter=Ary1D}, provided-interface=Ary1D_u9p7_7_CalPortIf1
      MotCtrlPrmEstimnMotInduDaxHiLim: parameter-provide-com-spec{init-value=0.00013, parameter=Val}, provided-interface=float32_CalPortIf1
      MotCtrlPrmEstimnMotInduDaxIvtrLoaMtgtn: parameter-provide-com-spec{init-value=0.00013, parameter=Val}, provided-interface=float32_CalPortIf1
      MotCtrlPrmEstimnMotInduDaxLoLim: parameter-provide-com-spec{init-value=0.0001, parameter=Val}, provided-interface=float32_CalPortIf1
      MotCtrlPrmEstimnMotInduDaxNom: parameter-provide-com-spec{init-value=0.00011889, parameter=Val}, provided-interface=float32_CalPortIf1
      MotCtrlPrmEstimnMotInduDaxSatnScaY: parameter-provide-com-spec{init-value=6 x [16384, 16384, 16384, 16384, 16384, 16305, 16096], parameter=Ary2D}, provided-interface=Ary2D_u2p14_6_7_CalPortIf1
      MotCtrlPrmEstimnMotInduQaxHiLim: parameter-provide-com-spec{init-value=0.00013, parameter=Val}, provided-interface=float32_CalPortIf1
      MotCtrlPrmEstimnMotInduQaxIvtrLoaMtgtn: parameter-provide-com-spec{init-value=0.00013, parameter=Val}, provided-interface=float32_CalPortIf1
      MotCtrlPrmEstimnMotInduQaxLoLim: parameter-provide-com-spec{init-value=0.0001, parameter=Val}, provided-interface=float32_CalPortIf1
      MotCtrlPrmEstimnMotInduQaxNom: parameter-provide-com-spec{init-value=0.00011889, parameter=Val}, provided-interface=float32_CalPortIf1
      MotCtrlPrmEstimnMotInduQaxSatnScaY: parameter-provide-com-spec{init-value=6 x [16384, 16384, 16384, 16384, 16384, 16305, 16096], parameter=Ary2D}, provided-interface=Ary2D_u2p14_6_7_CalPortIf1
      MotCtrlPrmEstimnMotRHiLim: parameter-provide-com-spec{init-value=0.032, parameter=Val}, provided-interface=float32_CalPortIf1
      MotCtrlPrmEstimnMotRLoLim: parameter-provide-com-spec{init-value=0.01246, parameter=Val}, provided-interface=float32_CalPortIf1
      MotCtrlPrmEstimnMotRNom: parameter-provide-com-spec{init-value=0.0139, parameter=Val}, provided-interface=float32_CalPortIf1
      MotCtrlPrmEstimnMotWidgThermCoeff: parameter-provide-com-spec{init-value=0.0039, parameter=Val}, provided-interface=float32_CalPortIf1
      MotCtrlPrmEstimnTNom: parameter-provide-com-spec{init-value=25, parameter=Val}, provided-interface=float32_CalPortIf1
      MotCurrPeakEstimnCurrFilFrq: parameter-provide-com-spec{init-value=8, parameter=Val}, provided-interface=float32_CalPortIf1
      MotCurrPeakEstimnCurrPeakEstimdFilFrq: parameter-provide-com-spec{init-value=0.03, parameter=Val}, provided-interface=float32_CalPortIf1
      MotCurrRegCfgCtrlrDynGainVehSpdCutOff: parameter-provide-com-spec{init-value=255, parameter=Val}, provided-interface=float32_CalPortIf1
      MotCurrRegCfgCurrLoopSecOrderTrfFctEna: parameter-provide-com-spec{init-value=1, parameter=Logl}, provided-interface=boolean_CalPortIf1
      MotCurrRegCfgIntglGainSampleTi: parameter-provide-com-spec{init-value=0.000125, parameter=Val}, provided-interface=float32_CalPortIf1
      MotCurrRegCfgMotAgCompuDly: parameter-provide-com-spec{init-value=9.375e-05, parameter=Val}, provided-interface=float32_CalPortIf1
      MotCurrRegCfgMotClsdLoopBwDaxY: parameter-provide-com-spec{init-value=[12800, 19200, 19200, 19200], parameter=Ary1D}, provided-interface=Ary1D_u10p6_4_CalPortIf1
      MotCurrRegCfgMotClsdLoopBwQaxY: parameter-provide-com-spec{init-value=[12800, 19200, 19200, 19200], parameter=Ary1D}, provided-interface=Ary1D_u10p6_4_CalPortIf1
      MotCurrRegCfgMotCtrlPrmSelnX: parameter-provide-com-spec{init-value=[0, 32, 160, 320], parameter=Ary1D}, provided-interface=Ary1D_u11p5_4_CalPortIf1
      MotCurrRegCfgMotDampgRatDax: parameter-provide-com-spec{init-value=1, parameter=Val}, provided-interface=float32_CalPortIf1
      MotCurrRegCfgMotDampgRatQax: parameter-provide-com-spec{init-value=1, parameter=Val}, provided-interface=float32_CalPortIf1
      MotCurrRegCfgMotNatFrqDaxY: parameter-provide-com-spec{init-value=[38400, 38400, 38400, 38400], parameter=Ary1D}, provided-interface=Ary1D_u9p7_4_CalPortIf1
      MotCurrRegCfgMotNatFrqQaxY: parameter-provide-com-spec{init-value=[38400, 38400, 38400, 38400], parameter=Ary1D}, provided-interface=Ary1D_u9p7_4_CalPortIf1
      MotCurrRegCfgMotRVirtDax: parameter-provide-com-spec{init-value=0, parameter=Val}, provided-interface=float32_CalPortIf1
      MotCurrRegCfgMotRVirtQax: parameter-provide-com-spec{init-value=0, parameter=Val}, provided-interface=float32_CalPortIf1
      MotCurrRegCfgMotVelFilFrq: parameter-provide-com-spec{init-value=10, parameter=Val}, provided-interface=float32_CalPortIf1
      MotCurrRegVltgLimrCurrLoaScarSlewRate: parameter-provide-com-spec{init-value=100, parameter=Val}, provided-interface=float32_CalPortIf1
      MotCurrRegVltgLimrDaxAntiWdupCoeff: parameter-provide-com-spec{init-value=0, parameter=Val}, provided-interface=float32_CalPortIf1
      MotCurrRegVltgLimrDualEcuLoaScarSlewRate: parameter-provide-com-spec{init-value=100, parameter=Val}, provided-interface=float32_CalPortIf1
      MotCurrRegVltgLimrIvtrLoaScarSlewRate: parameter-provide-com-spec{init-value=100, parameter=Val}, provided-interface=float32_CalPortIf1
      MotCurrRegVltgLimrMotCurrPredEna: parameter-provide-com-spec{init-value=0, parameter=Logl}, provided-interface=boolean_CalPortIf1
      MotCurrRegVltgLimrMotCurrPredTi: parameter-provide-com-spec{init-value=0, parameter=Val}, provided-interface=float32_CalPortIf1
      MotCurrRegVltgLimrMotCurrQaxRefMdfnRplEna: parameter-provide-com-spec{init-value=0, parameter=Logl}, provided-interface=boolean_CalPortIf1
      MotCurrRegVltgLimrMotVltgBrdgFilEna: parameter-provide-com-spec{init-value=1, parameter=Logl}, provided-interface=boolean_CalPortIf1
      MotCurrRegVltgLimrMotVltgBrdgLpFilFrq: parameter-provide-com-spec{init-value=200, parameter=Val}, provided-interface=float32_CalPortIf1
      MotCurrRegVltgLimrMotVltgDaxIntglHiLim: parameter-provide-com-spec{init-value=9, parameter=Val}, provided-interface=float32_CalPortIf1
      MotCurrRegVltgLimrMotVltgDaxIntglLoLim: parameter-provide-com-spec{init-value=-4.5, parameter=Val}, provided-interface=float32_CalPortIf1
      MotCurrRegVltgLimrMotVltgQaxFfFilEna: parameter-provide-com-spec{init-value=1, parameter=Logl}, provided-interface=boolean_CalPortIf1
      MotCurrRegVltgLimrMotVltgQaxFfLpFilFrq: parameter-provide-com-spec{init-value=500, parameter=Val}, provided-interface=float32_CalPortIf1
      MotCurrRegVltgLimrMotVltgQaxIntglHiLim: parameter-provide-com-spec{init-value=14.5, parameter=Val}, provided-interface=float32_CalPortIf1
      MotCurrRegVltgLimrMotVltgQaxIntglLoLim: parameter-provide-com-spec{init-value=-14.5, parameter=Val}, provided-interface=float32_CalPortIf1
      MotCurrRegVltgLimrQaxAntiWdupCoeff: parameter-provide-com-spec{init-value=0, parameter=Val}, provided-interface=float32_CalPortIf1
      MotCurrRegVltgLimrQaxAntiWdupScagDi: parameter-provide-com-spec{init-value=0, parameter=Logl}, provided-interface=boolean_CalPortIf1
      MotDrvDiagcErrFilFrq: parameter-provide-com-spec{init-value=1.8, parameter=Val}, provided-interface=float32_CalPortIf1
      MotDrvDiagcErrOffs: parameter-provide-com-spec{init-value=0, parameter=Val}, provided-interface=uint32_CalPortIf1
      MotDrvDiagcErrThd: parameter-provide-com-spec{init-value=180000, parameter=Val}, provided-interface=uint32_CalPortIf1
      MotQuadDetnMotDirHysInsts: parameter-provide-com-spec{init-value=20480, parameter=Val}, provided-interface=s18p13_CalPortIf1
      MotRefMdlCurrDaxBoostGain: parameter-provide-com-spec{init-value=0, parameter=Val}, provided-interface=float32_CalPortIf1
      MotRefMdlCurrDaxBoostTqScaX: parameter-provide-com-spec{init-value=[0, 6144, 7168, 8192, 9216, 10240, 12288, 14336, 16384, 18432, 20480], parameter=Ary1D}, provided-interface=Ary1D_u4p12_11_CalPortIf1
      MotRefMdlCurrDaxBoostTqScaY: parameter-provide-com-spec{init-value=[0, 16384, 19661, 22938, 23757, 25395, 27034, 27853, 29491, 31130, 32768], parameter=Ary1D}, provided-interface=Ary1D_u1p15_11_CalPortIf1
      MotRefMdlCurrDaxQaxRefDelta: parameter-provide-com-spec{init-value=[-3.1415927, -2.3561945, -1.5707964, -0.7853982, 0, 0.7853982, 1.5707964, 2.3561945], parameter=Ary1D}, provided-interface=Ary1D_float32_8_CalPortIf1
      MotRefMdlCurrItrnTolr: parameter-provide-com-spec{init-value=0.1, parameter=Val}, provided-interface=float32_CalPortIf1
      MotRefMdlFbCtrlDi: parameter-provide-com-spec{init-value=0, parameter=Logl}, provided-interface=boolean_CalPortIf1
      MotRefMdlIvtrDeadTiBrdgVltgSca: parameter-provide-com-spec{init-value=1, parameter=Val}, provided-interface=float32_CalPortIf1
      MotRefMdlMinCurrItrnLim: parameter-provide-com-spec{init-value=3, parameter=Val}, provided-interface=uint8_CalPortIf1
      MotRefMdlMotCurrDaxMaxSca: parameter-provide-com-spec{init-value=1, parameter=Val}, provided-interface=float32_CalPortIf1
      MotRefMdlMotVelLpFilFrq: parameter-provide-com-spec{init-value=125, parameter=Val}, provided-interface=float32_CalPortIf1
      MotRefMdlMotVltgDerivtvTiCon: parameter-provide-com-spec{init-value=0.0026526, parameter=Val}, provided-interface=float32_CalPortIf1
      MotRefMdlQuad13VltgSdlX: parameter-provide-com-spec{init-value=[0, 3200, 6400, 9600, 16000, 19200, 22400, 25600, 28800, 35200], parameter=Ary1D}, provided-interface=Ary1D_u11p5_10_CalPortIf1
      MotRefMdlQuad13VltgSdlY: parameter-provide-com-spec{init-value=10 x 0, parameter=Ary1D}, provided-interface=Ary1D_u3p13_10_CalPortIf1
      MotRefMdlQuad24VltgSdlX: parameter-provide-com-spec{init-value=[0, 3200, 6400, 9600, 16000, 19200, 22400, 25600, 28800, 35200], parameter=Ary1D}, provided-interface=Ary1D_u11p5_10_CalPortIf1
      MotRefMdlQuad24VltgSdlY: parameter-provide-com-spec{init-value=10 x 0, parameter=Ary1D}, provided-interface=Ary1D_u3p13_10_CalPortIf1
      MotRefMdlRefLocnItrnLim: parameter-provide-com-spec{init-value=10, parameter=Val}, provided-interface=uint8_CalPortIf1
      MotRefMdlTqItrnLim: parameter-provide-com-spec{init-value=3, parameter=Val}, provided-interface=uint8_CalPortIf1
      MotRefMdlTqItrnTolr: parameter-provide-com-spec{init-value=0.015, parameter=Val}, provided-interface=float32_CalPortIf1
      MotRefMdlVltgModDynCmpEna: parameter-provide-com-spec{init-value=0, parameter=Logl}, provided-interface=boolean_CalPortIf1
      MotRefMdlVltgOverRThdSca: parameter-provide-com-spec{init-value=0.25, parameter=Val}, provided-interface=float32_CalPortIf1
      MotRplCoggCfgMotAgTiDly: parameter-provide-com-spec{init-value=0, parameter=Val}, provided-interface=float32_CalPortIf1
      MotRplCoggCfgMotCurrDaxRplBilnrSeln: parameter-provide-com-spec{init-value=[0, 1280, 3200, 6400, 7680, 9600, 11520, 12800, 14080, 16000], parameter=Ary1D}, provided-interface=Ary1D_u9p7_10_CalPortIf1
      MotRplCoggCfgMotCurrQaxRpl: parameter-provide-com-spec{init-value=[0, 1280, 3200, 6400, 7680, 9600, 12800, 13440, 14080, 15360, 16000, 17280], parameter=Ary1D}, provided-interface=Ary1D_u9p7_12_CalPortIf1
      MotRplCoggCfgMotTqCmdCurrRgltrBwCmpMgnY: parameter-provide-com-spec{init-value=20 x 8 x 0, parameter=Ary2D}, provided-interface=Ary2D_u3p13_20_8_CalPortIf1
      MotRplCoggCfgMotTqCmdCurrRgltrBwCmpPhaY: parameter-provide-com-spec{init-value=20 x 8 x 0, parameter=Ary2D}, provided-interface=Ary2D_u0p16_20_8_CalPortIf1
      MotRplCoggCfgMotTqCmdCurrRgltrBwCmpX: parameter-provide-com-spec{init-value=[0, 1024, 2048, 4096, 6144, 8192, 9216, 10240], parameter=Ary1D}, provided-interface=Ary1D_u5p11_8_CalPortIf1
      MotRplCoggCfgMotTqRplOrder1X: parameter-provide-com-spec{init-value=10 x 12 x 0, parameter=Ary2D}, provided-interface=Ary2D_s1p14_10_12_CalPortIf1
      MotRplCoggCfgMotTqRplOrder1Y: parameter-provide-com-spec{init-value=10 x 12 x 0, parameter=Ary2D}, provided-interface=Ary2D_s1p14_10_12_CalPortIf1
      MotRplCoggCfgMotTqRplOrder2X: parameter-provide-com-spec{init-value=10 x 12 x 0, parameter=Ary2D}, provided-interface=Ary2D_s1p14_10_12_CalPortIf1
      MotRplCoggCfgMotTqRplOrder2Y: parameter-provide-com-spec{init-value=10 x 12 x 0, parameter=Ary2D}, provided-interface=Ary2D_s1p14_10_12_CalPortIf1
      MotRplCoggCfgMotTqRplOrder3X: parameter-provide-com-spec{init-value=10 x 12 x 0, parameter=Ary2D}, provided-interface=Ary2D_s1p14_10_12_CalPortIf1
      MotRplCoggCfgMotTqRplOrder3Y: parameter-provide-com-spec{init-value=10 x 12 x 0, parameter=Ary2D}, provided-interface=Ary2D_s1p14_10_12_CalPortIf1
      MotRplCoggCfgMotVelBilnrSeln: parameter-provide-com-spec{init-value=[0, 100, 114, 303, 800, 1200, 2600, 3200, 3700, 4200, 5000, 6000, 7200, 7500, 8000, 8500, 9000, 9500, 10000, 11000], parameter=Ary1D}, provided-interface=Ary1D_u16p0_20_CalPortIf1
      MotRplCoggCmdHrmncOrder1Elec: parameter-provide-com-spec{init-value=6, parameter=Val}, provided-interface=uint8_CalPortIf1
      MotRplCoggCmdHrmncOrder2Elec: parameter-provide-com-spec{init-value=12, parameter=Val}, provided-interface=uint8_CalPortIf1
      MotRplCoggCmdHrmncOrder3Elec: parameter-provide-com-spec{init-value=18, parameter=Val}, provided-interface=uint8_CalPortIf1
      MotTqCmdScaMax: parameter-provide-com-spec{init-value=1.1, parameter=Val}, provided-interface=float32_CalPortIf1
      MotTqCmdScaMin: parameter-provide-com-spec{init-value=0.9, parameter=Val}, provided-interface=float32_CalPortIf1
      MotTqTranlDampgVehSpdBlndY: parameter-provide-com-spec{init-value=[16384, 16384, 0, 0], parameter=Ary1D}, provided-interface=Ary1D_u2p14_4_CalPortIf1
      NxtrCalIdsCal0DevlpAuthor: parameter-provide-com-spec{init-value=6 x 0, parameter=Ary1D}, provided-interface=Ary1D_u8_6_CalPortIf1
      NxtrCalIdsCal0DevlpDesc: parameter-provide-com-spec{init-value=48 x 0, parameter=Ary1D}, provided-interface=Ary1D_u8_48_CalPortIf1
      NxtrCalIdsCal0DevlpRelNr: parameter-provide-com-spec{init-value=0, parameter=Val}, provided-interface=uint32_CalPortIf1
      NxtrCalIdsCal0DevlpRelSt: parameter-provide-com-spec{init-value=0, parameter=Val}, provided-interface=uint8_CalPortIf1
      NxtrCalIdsCal0DevlpTiStamp: parameter-provide-com-spec{init-value=0, parameter=Val}, provided-interface=uint32_CalPortIf1
      NxtrCalIdsCal0DevlpVers: parameter-provide-com-spec{init-value=0, parameter=Val}, provided-interface=uint8_CalPortIf1
      PwrDiscnctOpenThd: parameter-provide-com-spec{init-value=2, parameter=Val}, provided-interface=float32_CalPortIf1
      PwrLimrAssiRednLpFilFrq: parameter-provide-com-spec{init-value=0.365, parameter=Val}, provided-interface=float32_CalPortIf1
      PwrLimrBackEmfConStdT: parameter-provide-com-spec{init-value=0.0335999, parameter=Val}, provided-interface=float32_CalPortIf1
      PwrLimrBrdgVltgAdjSlew: parameter-provide-com-spec{init-value=0.5, parameter=Val}, provided-interface=float32_CalPortIf1
      PwrLimrBrdgVltgAltFltAdj: parameter-provide-com-spec{init-value=1, parameter=Val}, provided-interface=float32_CalPortIf1
      PwrLimrFilAssiRednThd: parameter-provide-com-spec{init-value=0.6, parameter=Val}, provided-interface=float32_CalPortIf1
      PwrLimrLoVoltAssiRcvrThd: parameter-provide-com-spec{init-value=13.5, parameter=Val}, provided-interface=float32_CalPortIf1
      PwrLimrLoVoltAssiRcvrTi: parameter-provide-com-spec{init-value=2000, parameter=Val}, provided-interface=uint16_CalPortIf1
      PwrLimrMotEnvlpX: parameter-provide-com-spec{init-value=[-17600, -12800, -10400, -8800, -5657, -4600, -3499, -1731, 0, 1731, 3499, 4600, 5657, 8800], parameter=Ary1D}, provided-interface=Ary1D_s11p4_14_CalPortIf1
      PwrLimrMotEnvlpY: parameter-provide-com-spec{init-value=[1475, 2867, 3891, 4710, 7168, 8397, 9486, 9486, 9486, 9486, 7277, 5994, 4506, 0], parameter=Ary1D}, provided-interface=Ary1D_u5p11_14_CalPortIf1
      PwrLimrMotVelLpFilFrq: parameter-provide-com-spec{init-value=100, parameter=Val}, provided-interface=float32_CalPortIf1
      PwrLimrSpdAdjSlewDec: parameter-provide-com-spec{init-value=3.125, parameter=Val}, provided-interface=float32_CalPortIf1
      PwrLimrSpdAdjSlewEna: parameter-provide-com-spec{init-value=1, parameter=Logl}, provided-interface=boolean_CalPortIf1
      PwrLimrSpdAdjSlewInc: parameter-provide-com-spec{init-value=3125, parameter=Val}, provided-interface=float32_CalPortIf1
      PwrLimrStdOperMotEnvlpX: parameter-provide-com-spec{init-value=[0, 2182, 5717, 7919, 10034, 16320], parameter=Ary1D}, provided-interface=Ary1D_u11p5_6_CalPortIf1
      PwrLimrStdOperMotEnvlpY: parameter-provide-com-spec{init-value=[18973, 18973, 14553, 11989, 9011, 0], parameter=Ary1D}, provided-interface=Ary1D_u4p12_6_CalPortIf1
      PwrLimrVltgDptMotVelOffsX: parameter-provide-com-spec{init-value=[17496, 18728, 18928, 19136, 19336, 19544, 20568, 21592, 22208, 25280], parameter=Ary1D}, provided-interface=Ary1D_u5p11_10_CalPortIf1
      PwrLimrVltgDptMotVelOffsY: parameter-provide-com-spec{init-value=[3395, 2859, 2769, 2680, 2591, 2501, 2054, 1608, 1340, 0], parameter=Ary1D}, provided-interface=Ary1D_u11p5_10_CalPortIf1
      PwrSplyNtc0x07BFailStep: parameter-provide-com-spec{init-value=13106, parameter=Val}, provided-interface=uint16_CalPortIf1
      PwrSplyNtc0x07BPassStep: parameter-provide-com-spec{init-value=13106, parameter=Val}, provided-interface=uint16_CalPortIf1
      PwrSplyNtc0x07CFailStep: parameter-provide-com-spec{init-value=13106, parameter=Val}, provided-interface=uint16_CalPortIf1
      PwrSplyNtc0x07CPassStep: parameter-provide-com-spec{init-value=13106, parameter=Val}, provided-interface=uint16_CalPortIf1
      PwrSplyNtc0x07DFailStep: parameter-provide-com-spec{init-value=13106, parameter=Val}, provided-interface=uint16_CalPortIf1
      PwrSplyNtc0x07DPassStep: parameter-provide-com-spec{init-value=13106, parameter=Val}, provided-interface=uint16_CalPortIf1
      SinVltgGennDthrLpFilCoeff: parameter-provide-com-spec{init-value=0.625, parameter=Val}, provided-interface=float32_CalPortIf1
      SnsrOffsLrngSampleCntForHwTqLrngRst: parameter-provide-com-spec{init-value=2000, parameter=Val}, provided-interface=uint16_CalPortIf1
      StHlthSigNormnAbsltMotPosDifStHlthDiagThd: parameter-provide-com-spec{init-value=67, parameter=Val}, provided-interface=uint8_CalPortIf1
      StHlthSigNormnCurrMotSumStHlthDiagThd: parameter-provide-com-spec{init-value=67, parameter=Val}, provided-interface=uint8_CalPortIf1
      StHlthSigNormnDigTqStHlthDiagThd: parameter-provide-com-spec{init-value=67, parameter=Val}, provided-interface=uint8_CalPortIf1
      StHlthSigNormnDutyCycFltLimThd: parameter-provide-com-spec{init-value=84, parameter=Val}, provided-interface=u16p0_CalPortIf1
      StHlthSigNormnIdptSigStHlthSca: parameter-provide-com-spec{init-value=22, parameter=Val}, provided-interface=uint8_CalPortIf1
      StHlthSigNormnMaxFricThd: parameter-provide-com-spec{init-value=15, parameter=Val}, provided-interface=float32_CalPortIf1
      StHlthSigNormnMinRackTrvlLim: parameter-provide-com-spec{init-value=5, parameter=Val}, provided-interface=float32_CalPortIf1
      StHlthSigNormnMotPosStHlthDiagThd: parameter-provide-com-spec{init-value=67, parameter=Val}, provided-interface=uint8_CalPortIf1
      StHlthSigNormnMotVelCal: parameter-provide-com-spec{init-value=20, parameter=Val}, provided-interface=float32_CalPortIf1
      StHlthSigNormnPhaInfoStHlthDiagThd: parameter-provide-com-spec{init-value=67, parameter=Val}, provided-interface=uint8_CalPortIf1
      StHlthSigNormnStHlthCorrlnErr: parameter-provide-com-spec{init-value=0, parameter=Val}, provided-interface=u0p16_CalPortIf1
      StHlthSigNormnStHlthCurrMotSum: parameter-provide-com-spec{init-value=0, parameter=Val}, provided-interface=float32_CalPortIf1
      StHlthSigNormnStHlthPhaInfo: parameter-provide-com-spec{init-value=0, parameter=Val}, provided-interface=float32_CalPortIf1
      StHlthSigNormnValMaxStHlthErr: parameter-provide-com-spec{init-value=3.48, parameter=Val}, provided-interface=float32_CalPortIf1
      StHlthSigNormnValMinStHlthErr: parameter-provide-com-spec{init-value=0.62, parameter=Val}, provided-interface=float32_CalPortIf1
      StHlthSigNormnWhlImbRejctnThd: parameter-provide-com-spec{init-value=5, parameter=Val}, provided-interface=float32_CalPortIf1
      SysGlbPrmVehSpdBilnrSeln: parameter-provide-com-spec{init-value=[0, 640, 1920, 3840, 7680, 10240, 12800, 15360, 19200, 23040, 25600, 28160], parameter=Ary1D}, provided-interface=Ary1D_u9p7_12_CalPortIf1
      TqOscnAmpLimY: parameter-provide-com-spec{init-value=[819, 1024, 1229, 1434, 1434], parameter=Ary1D}, provided-interface=Ary1D_u5p11_5_CalPortIf1
      TqOscnFallRampRateCal: parameter-provide-com-spec{init-value=-4400, parameter=Val}, provided-interface=float32_CalPortIf1
      TqOscnFrqIn: parameter-provide-com-spec{init-value=[2560, 3840, 5120, 10240, 12800], parameter=Ary1D}, provided-interface=Ary1D_u8p8_5_CalPortIf1
      TqOscnRisngRampRateCal: parameter-provide-com-spec{init-value=4400, parameter=Val}, provided-interface=float32_CalPortIf1
      TqOscnUseRampRateCal: parameter-provide-com-spec{init-value=1, parameter=Logl}, provided-interface=boolean_CalPortIf1
      TSG31CfgAndUseAdcStrtOfCnvn2Offs: parameter-provide-com-spec{init-value=5000, parameter=Val}, provided-interface=uint32_CalPortIf1
      TSG31CfgAndUseAdcStrtOfCnvnMotCtrlPeakOffs: parameter-provide-com-spec{init-value=6000, parameter=Val}, provided-interface=uint32_CalPortIf1
      TSG31CfgAndUseAdcStrtOfCnvnMotCtrlVlyOffs: parameter-provide-com-spec{init-value=7000, parameter=Val}, provided-interface=uint32_CalPortIf1
      TSG31CfgAndUseMtrAg0SPIStart: parameter-provide-com-spec{init-value=1000, parameter=Val}, provided-interface=uint32_CalPortIf1
      TSG31CfgAndUsePwmDbnd: parameter-provide-com-spec{init-value=200, parameter=Val}, provided-interface=uint32_CalPortIf1
      TunSelnAuthyTunSelnRtDiCmd: parameter-provide-com-spec{init-value=0, parameter=Logl}, provided-interface=boolean_CalPortIf1
      VehSigCdngDftLatA: parameter-provide-com-spec{init-value=0, parameter=Val}, provided-interface=float32_CalPortIf1
      VehSigCdngDftLgtA: parameter-provide-com-spec{init-value=0, parameter=Val}, provided-interface=float32_CalPortIf1
      VehSigCdngDftVehSpd: parameter-provide-com-spec{init-value=100, parameter=Val}, provided-interface=float32_CalPortIf1
      VehSigCdngDftYawRate: parameter-provide-com-spec{init-value=0, parameter=Val}, provided-interface=float32_CalPortIf1
      VehSigCdngLatADifThd: parameter-provide-com-spec{init-value=0.2, parameter=Val}, provided-interface=float32_CalPortIf1
      VehSigCdngLatAFilFrq: parameter-provide-com-spec{init-value=100, parameter=Val}, provided-interface=float32_CalPortIf1
      VehSigCdngLtgADifThd: parameter-provide-com-spec{init-value=1, parameter=Val}, provided-interface=float32_CalPortIf1
      VehSigCdngVehSpdDifThd: parameter-provide-com-spec{init-value=5, parameter=Val}, provided-interface=float32_CalPortIf1
      VehSigCdngVehYawSlewRate: parameter-provide-com-spec{init-value=120, parameter=Val}, provided-interface=float32_CalPortIf1
      VehSigCdngYawRateDifThd: parameter-provide-com-spec{init-value=20, parameter=Val}, provided-interface=float32_CalPortIf1
      VehSpdLimrMaxAssiX: parameter-provide-com-spec{init-value=[0, 3200, 6400, 8320, 9600], parameter=Ary1D}, provided-interface=Ary1D_u9p7_5_CalPortIf1
      VehSpdLimrMaxAssiY: parameter-provide-com-spec{init-value=5 x 18022, parameter=Ary1D}, provided-interface=Ary1D_u5p11_5_CalPortIf1
      VehSpdLimrPosMaxOffs1: parameter-provide-com-spec{init-value=140, parameter=Val}, provided-interface=float32_CalPortIf1
      VehSpdLimrPosMaxOffs2: parameter-provide-com-spec{init-value=120, parameter=Val}, provided-interface=float32_CalPortIf1
      WhlImbRejctnFrqDiagcLpFil: parameter-provide-com-spec{init-value=2, parameter=Val}, provided-interface=float32_CalPortIf1
